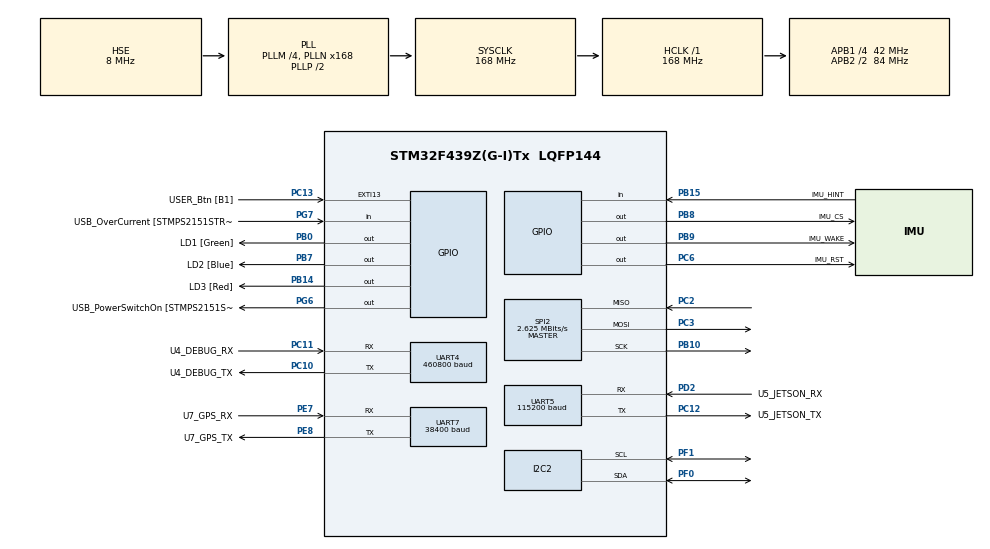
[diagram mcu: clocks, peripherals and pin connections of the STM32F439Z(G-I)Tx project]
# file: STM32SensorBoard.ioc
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Dma.Request0=UART4_TX
Dma.Request1=UART5_TX
Dma.Request2=UART7_RX
Dma.Request3=UART5_RX
Dma.Request4=UART4_RX
Dma.Request5=UART7_TX
Dma.UART4_RX.4.Direction=DMA_PERIPH_TO_MEMORY
Dma.UART4_RX.4.FIFOMode=DMA_FIFOMODE_DISABLE
Dma.UART4_RX.4.Instance=DMA1_Stream2
Dma.UART4_RX.4.MemDataAlignment=DMA_MDATAALIGN_BYTE
Dma.UART4_RX.4.MemInc=DMA_MINC_ENABLE
Dma.UART4_RX.4.Mode=DMA_NORMAL
Dma.UART4_RX.4.PeriphDataAlignment=DMA_PDATAALIGN_BYTE
Dma.UART4_RX.4.PeriphInc=DMA_PINC_DISABLE
Dma.UART4_RX.4.Priority=DMA_PRIORITY_LOW
Dma.UART4_TX.0.Direction=DMA_MEMORY_TO_PERIPH
Dma.UART4_TX.0.FIFOMode=DMA_FIFOMODE_DISABLE
Dma.UART4_TX.0.Instance=DMA1_Stream4
Dma.UART4_TX.0.MemDataAlignment=DMA_MDATAALIGN_BYTE
Dma.UART4_TX.0.MemInc=DMA_MINC_ENABLE
Dma.UART4_TX.0.Mode=DMA_NORMAL
Dma.UART4_TX.0.PeriphDataAlignment=DMA_PDATAALIGN_BYTE
Dma.UART4_TX.0.PeriphInc=DMA_PINC_DISABLE
Dma.UART4_TX.0.Priority=DMA_PRIORITY_LOW
Dma.UART5_RX.3.Direction=DMA_PERIPH_TO_MEMORY
Dma.UART5_RX.3.FIFOMode=DMA_FIFOMODE_DISABLE
Dma.UART5_RX.3.Instance=DMA1_Stream0
Dma.UART5_RX.3.MemDataAlignment=DMA_MDATAALIGN_BYTE
Dma.UART5_RX.3.MemInc=DMA_MINC_ENABLE
Dma.UART5_RX.3.Mode=DMA_NORMAL
Dma.UART5_RX.3.PeriphDataAlignment=DMA_PDATAALIGN_BYTE
Dma.UART5_RX.3.PeriphInc=DMA_PINC_DISABLE
Dma.UART5_RX.3.Priority=DMA_PRIORITY_LOW
Dma.UART5_TX.1.Direction=DMA_MEMORY_TO_PERIPH
Dma.UART5_TX.1.FIFOMode=DMA_FIFOMODE_DISABLE
Dma.UART5_TX.1.Instance=DMA1_Stream7
Dma.UART5_TX.1.MemDataAlignment=DMA_MDATAALIGN_BYTE
Dma.UART5_TX.1.MemInc=DMA_MINC_ENABLE
Dma.UART5_TX.1.Mode=DMA_NORMAL
Dma.UART5_TX.1.PeriphDataAlignment=DMA_PDATAALIGN_BYTE
Dma.UART5_TX.1.PeriphInc=DMA_PINC_DISABLE
Dma.UART5_TX.1.Priority=DMA_PRIORITY_HIGH
Dma.UART7_RX.2.Direction=DMA_PERIPH_TO_MEMORY
Dma.UART7_RX.2.FIFOMode=DMA_FIFOMODE_DISABLE
Dma.UART7_RX.2.Instance=DMA1_Stream3
Dma.UART7_RX.2.MemDataAlignment=DMA_MDATAALIGN_BYTE
Dma.UART7_RX.2.MemInc=DMA_MINC_ENABLE
Dma.UART7_RX.2.Mode=DMA_NORMAL
Dma.UART7_RX.2.PeriphDataAlignment=DMA_PDATAALIGN_BYTE
Dma.UART7_RX.2.PeriphInc=DMA_PINC_DISABLE
Dma.UART7_RX.2.Priority=DMA_PRIORITY_MEDIUM
Dma.UART7_TX.5.Direction=DMA_MEMORY_TO_PERIPH
Dma.UART7_TX.5.FIFOMode=DMA_FIFOMODE_DISABLE
Dma.UART7_TX.5.Instance=DMA1_Stream1
Dma.UART7_TX.5.MemDataAlignment=DMA_MDATAALIGN_BYTE
Dma.UART7_TX.5.MemInc=DMA_MINC_ENABLE
Dma.UART7_TX.5.Mode=DMA_NORMAL
Dma.UART7_TX.5.PeriphDataAlignment=DMA_PDATAALIGN_BYTE
Dma.UART7_TX.5.PeriphInc=DMA_PINC_DISABLE
Dma.UART7_TX.5.Priority=DMA_PRIORITY_LOW
FREERTOS.Tasks01=appMain,24,128,StartAppMainTask,As weak,NULL,Dynamic,NULL,NULL
FREERTOS.configUSE_NEWLIB_REENTRANT=1
Mcu.Family=STM32F4
Mcu.Name=STM32F439Z(G-I)Tx
Mcu.Package=LQFP144
NVIC.DMA1_Stream0_IRQn=true\:5\:0\:false\:false\:true\:true\:false\:true\:true
NVIC.DMA1_Stream1_IRQn=true\:5\:0\:false\:false\:true\:true\:false\:true\:true
NVIC.DMA1_Stream2_IRQn=true\:5\:0\:false\:false\:true\:true\:false\:true\:true
NVIC.DMA1_Stream3_IRQn=true\:5\:0\:false\:false\:true\:true\:false\:true\:true
NVIC.DMA1_Stream4_IRQn=true\:5\:0\:false\:false\:true\:true\:false\:true\:true
NVIC.DMA1_Stream7_IRQn=true\:5\:0\:false\:false\:true\:true\:false\:true\:true
NVIC.PriorityGroup=NVIC_PRIORITYGROUP_4
NVIC.TIM7_IRQn=true\:15\:0\:false\:false\:true\:false\:false\:true\:true
NVIC.TimeBase=TIM7_IRQn
NVIC.TimeBaseIP=TIM7
NVIC.UART4_IRQn=true\:5\:0\:false\:false\:true\:true\:true\:true\:true
NVIC.UART5_IRQn=true\:5\:0\:false\:false\:true\:true\:true\:true\:true
NVIC.UART7_IRQn=true\:5\:0\:false\:false\:true\:true\:true\:true\:true
PA1.GPIO_Label=RMII_REF_CLK [LAN8742A-CZ-TR_REFCLK0]
PA1.Signal=ETH_REF_CLK
PA10.GPIO_Label=USB_ID
PA10.Signal=USB_OTG_FS_ID
PA11.GPIO_Label=USB_DM
PA11.Signal=USB_OTG_FS_DM
PA12.GPIO_Label=USB_DP
PA12.Signal=USB_OTG_FS_DP
PA13.GPIO_Label=TMS
PA13.Mode=Serial_Wire
PA13.Signal=SYS_JTMS-SWDIO
PA14.GPIO_Label=TCK
PA14.Mode=Serial_Wire
PA14.Signal=SYS_JTCK-SWCLK
PA2.GPIO_Label=RMII_MDIO [LAN8742A-CZ-TR_MDIO]
PA2.Signal=ETH_MDIO
PA7.GPIO_Label=RMII_CRS_DV [LAN8742A-CZ-TR_CRS_DV]
PA7.Signal=ETH_CRS_DV
PA8.GPIO_Label=USB_SOF [TP1]
PA8.Signal=USB_OTG_FS_SOF
PA9.GPIO_Label=USB_VBUS
PA9.Signal=USB_OTG_FS_VBUS
PB0.GPIO_Label=LD1 [Green]
PB0.Signal=GPIO_Output
PB10.Mode=Full_Duplex_Master
PB10.Signal=SPI2_SCK
PB13.GPIO_Label=RMII_TXD1 [LAN8742A-CZ-TR_TXD1]
PB13.Signal=ETH_TXD1
PB14.GPIO_Label=LD3 [Red]
PB14.Signal=GPIO_Output
PB15.GPIO_Label=IMU_HINT
PB15.Signal=GPIO_Input
PB7.GPIO_Label=LD2 [Blue]
PB7.Signal=GPIO_Output
PB8.GPIO_Label=IMU_CS
PB8.Signal=GPIO_Output
PB9.GPIO_Label=IMU_WAKE
PB9.Signal=GPIO_Output
PC1.GPIO_Label=RMII_MDC [LAN8742A-CZ-TR_MDC]
PC1.Signal=ETH_MDC
PC10.GPIO_Label=U4_DEBUG_TX
PC10.Mode=Asynchronous
PC10.Signal=UART4_TX
PC11.GPIO_Label=U4_DEBUG_RX
PC11.Mode=Asynchronous
PC11.Signal=UART4_RX
PC12.GPIO_Label=U5_JETSON_TX
PC12.Mode=Asynchronous
PC12.Signal=UART5_TX
PC13.GPIO_Label=USER_Btn [B1]
PC13.Signal=GPXTI13
PC14/OSC32_IN.Mode=LSE-External-Oscillator
PC14/OSC32_IN.Signal=RCC_OSC32_IN
PC15/OSC32_OUT.Mode=LSE-External-Oscillator
PC15/OSC32_OUT.Signal=RCC_OSC32_OUT
PC2.Mode=Full_Duplex_Master
PC2.Signal=SPI2_MISO
PC3.Mode=Full_Duplex_Master
PC3.Signal=SPI2_MOSI
PC4.GPIO_Label=RMII_RXD0 [LAN8742A-CZ-TR_RXD0]
PC4.Signal=ETH_RXD0
PC5.GPIO_Label=RMII_RXD1 [LAN8742A-CZ-TR_RXD1]
PC5.Signal=ETH_RXD1
PC6.GPIO_Label=IMU_RST
PC6.Signal=GPIO_Output
PD2.GPIO_Label=U5_JETSON_RX
PD2.Mode=Asynchronous
PD2.Signal=UART5_RX
PD8.GPIO_Label=STLK_RX [STM32F103CBT6_PA3]
PD8.Signal=USART3_TX
PD9.GPIO_Label=STLK_TX [STM32F103CBT6_PA2]
PD9.Signal=USART3_RX
PE7.GPIO_Label=U7_GPS_RX
PE7.Mode=Asynchronous
PE7.Signal=UART7_RX
PE8.GPIO_Label=U7_GPS_TX
PE8.Mode=Asynchronous
PE8.Signal=UART7_TX
PF0.Mode=I2C
PF0.Signal=I2C2_SDA
PF1.Mode=I2C
PF1.Signal=I2C2_SCL
PG11.GPIO_Label=RMII_TX_EN [LAN8742A-CZ-TR_TXEN]
PG11.Signal=ETH_TX_EN
PG13.GPIO_Label=RMII_TXD0 [LAN8742A-CZ-TR_TXD0]
PG13.Signal=ETH_TXD0
PG6.GPIO_Label=USB_PowerSwitchOn [STMPS2151STR_EN]
PG6.Signal=GPIO_Output
PG7.GPIO_Label=USB_OverCurrent [STMPS2151STR_FAULT]
PG7.Signal=GPIO_Input
PH0/OSC_IN.GPIO_Label=MCO [STM32F103CBT6_PA8]
PH0/OSC_IN.Mode=HSE-External-Clock-Source
PH0/OSC_IN.Signal=RCC_OSC_IN
PH1/OSC_OUT.Mode=HSE-External-Clock-Source
PH1/OSC_OUT.Signal=RCC_OSC_OUT
ProjectManager.HeapSize=0x200
ProjectManager.StackSize=0x400
ProjectManager.TargetToolchain=CMake
RCC.48MHZClocksFreq_Value=48000000
RCC.AHBFreq_Value=168000000
RCC.APB1CLKDivider=RCC_HCLK_DIV4
RCC.APB1Freq_Value=42000000
RCC.APB1TimFreq_Value=84000000
RCC.APB2CLKDivider=RCC_HCLK_DIV2
RCC.APB2Freq_Value=84000000
RCC.APB2TimCLKDivider=2
RCC.APB2TimFreq_Value=168000000
RCC.CortexFreq_Value=168000000
RCC.HCLKFreq_Value=168000000
RCC.HSE_VALUE=8000000
RCC.HSI_VALUE=16000000
RCC.PLLM=4
RCC.PLLMUL=RCC_PLL_MUL9
RCC.PLLN=168
RCC.PLLQ=7
RCC.PLLSourceVirtual=RCC_PLLSOURCE_HSE
RCC.PRESCALERUSB=RCC_USBCLKSOURCE_PLL_DIV1_5
RCC.SYSCLKFreq_VALUE=168000000
RCC.SYSCLKSource=RCC_SYSCLKSOURCE_PLLCLK
RCC.SYSCLKSourceVirtual=RCC_SYSCLKSOURCE_PLLCLK
RCC.USBFreq_Value=48000000
RCC.VCOOutputFreq_Value=336000000
SPI2.BaudRatePrescaler=SPI_BAUDRATEPRESCALER_16
SPI2.CalculateBaudRate=2.625 MBits/s
SPI2.Direction=SPI_DIRECTION_2LINES
SPI2.Mode=SPI_MODE_MASTER
SPI2.VirtualType=VM_MASTER
UART4.BaudRate=460800
UART4.VirtualMode=Asynchronous
UART5.BaudRate=115200
UART5.VirtualMode=Asynchronous
UART7.BaudRate=38400
UART7.VirtualMode=Asynchronous
VP_FREERTOS_VS_CMSIS_V2.Mode=CMSIS_V2
VP_SYS_VS_tim7.Mode=TIM7
board=NUCLEO-F439ZI

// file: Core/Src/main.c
/* USER CODE BEGIN Header */
/**
  ******************************************************************************
  * @file           : main.c
  * @brief          : Main program body
  ******************************************************************************
  * @attention
  *
  * Copyright (c) 2026 STMicroelectronics.
  * All rights reserved.
  *
  * This software is licensed under terms that can be found in the LICENSE file
  * in the root directory of this software component.
  * If no LICENSE file comes with this software, it is provided AS-IS.
  *
  ******************************************************************************
  */
/* USER CODE END Header */
#include "main.h"
#include "cmsis_os.h"

/* USER CODE BEGIN Includes */
#include "appmain.h"
/* USER CODE END Includes */

I2C_HandleTypeDef hi2c2;

UART_HandleTypeDef huart4;
UART_HandleTypeDef huart5;
UART_HandleTypeDef huart7;
DMA_HandleTypeDef hdma_uart4_tx;
DMA_HandleTypeDef hdma_uart4_rx;
DMA_HandleTypeDef hdma_uart5_tx;
DMA_HandleTypeDef hdma_uart5_rx;
DMA_HandleTypeDef hdma_uart7_rx;
DMA_HandleTypeDef hdma_uart7_tx;

/* Definitions for appMain */
osThreadId_t appMainHandle;
const osThreadAttr_t appMain_attributes = {
  .name = "appMain",
  .stack_size = 128 * 4,
  .priority = (osPriority_t) osPriorityNormal,
};

void SystemClock_Config(void);
static void MX_GPIO_Init(void);
static void MX_DMA_Init(void);
static void MX_UART4_Init(void);
static void MX_UART5_Init(void);
static void MX_UART7_Init(void);
static void MX_SPI2_Init(void);
static void MX_I2C2_Init(void);
void StartAppMainTask(void *argument);

int main(void)
{

  /* MCU Configuration--------------------------------------------------------*/

  /* Reset of all peripherals, Initializes the Flash interface and the Systick. */
  HAL_Init();

  /* Configure the system clock */
  SystemClock_Config();

  /* Initialize all configured peripherals */
  MX_GPIO_Init();
  MX_DMA_Init();
  MX_UART4_Init();
  MX_UART5_Init();
  MX_UART7_Init();
  MX_SPI2_Init();
  MX_I2C2_Init();

  /* Init scheduler */
  osKernelInitialize();

  /* Create the thread(s) */
  /* creation of appMain */
  appMainHandle = osThreadNew(StartAppMainTask, NULL, &appMain_attributes);

  /* USER CODE BEGIN RTOS_THREADS */
  AppSetup();
  /* USER CODE END RTOS_THREADS */

  /* Start scheduler */
  osKernelStart();

  /* We should never get here as control is now taken by the scheduler */

  /* Infinite loop */
  while (1)
  {

  }
}

void SystemClock_Config(void)
{
  RCC_OscInitTypeDef RCC_OscInitStruct = {0};
  RCC_ClkInitTypeDef RCC_ClkInitStruct = {0};

  /** Configure the main internal regulator output voltage
  */
  __HAL_RCC_PWR_CLK_ENABLE();
  __HAL_PWR_VOLTAGESCALING_CONFIG(PWR_REGULATOR_VOLTAGE_SCALE1);

  /** Initializes the RCC Oscillators according to the specified parameters
  * in the RCC_OscInitTypeDef structure.
  */
  RCC_OscInitStruct.OscillatorType = RCC_OSCILLATORTYPE_HSE;
  RCC_OscInitStruct.HSEState = RCC_HSE_BYPASS;
  RCC_OscInitStruct.PLL.PLLState = RCC_PLL_ON;
  RCC_OscInitStruct.PLL.PLLSource = RCC_PLLSOURCE_HSE;
  RCC_OscInitStruct.PLL.PLLM = 4;
  RCC_OscInitStruct.PLL.PLLN = 168;
  RCC_OscInitStruct.PLL.PLLP = RCC_PLLP_DIV2;
  RCC_OscInitStruct.PLL.PLLQ = 7;
  if (HAL_RCC_OscConfig(&RCC_OscInitStruct) != HAL_OK)
  {
    Error_Handler();
  }

  /** Initializes the CPU, AHB and APB buses clocks
  */
  RCC_ClkInitStruct.ClockType = RCC_CLOCKTYPE_HCLK|RCC_CLOCKTYPE_SYSCLK
                              |RCC_CLOCKTYPE_PCLK1|RCC_CLOCKTYPE_PCLK2;
  RCC_ClkInitStruct.SYSCLKSource = RCC_SYSCLKSOURCE_PLLCLK;
  RCC_ClkInitStruct.AHBCLKDivider = RCC_SYSCLK_DIV1;
  RCC_ClkInitStruct.APB1CLKDivider = RCC_HCLK_DIV4;
  RCC_ClkInitStruct.APB2CLKDivider = RCC_HCLK_DIV2;

  if (HAL_RCC_ClockConfig(&RCC_ClkInitStruct, FLASH_LATENCY_5) != HAL_OK)
  {
    Error_Handler();
  }
}

static void MX_I2C2_Init(void)
{

  hi2c2.Instance = I2C2;
  hi2c2.Init.ClockSpeed = 100000;
  hi2c2.Init.DutyCycle = I2C_DUTYCYCLE_2;
  hi2c2.Init.OwnAddress1 = 0;
  hi2c2.Init.AddressingMode = I2C_ADDRESSINGMODE_7BIT;
  hi2c2.Init.DualAddressMode = I2C_DUALADDRESS_DISABLE;
  hi2c2.Init.OwnAddress2 = 0;
  hi2c2.Init.GeneralCallMode = I2C_GENERALCALL_DISABLE;
  hi2c2.Init.NoStretchMode = I2C_NOSTRETCH_DISABLE;
  if (HAL_I2C_Init(&hi2c2) != HAL_OK)
  {
    Error_Handler();
  }

  /** Configure Analogue filter
  */
  if (HAL_I2CEx_ConfigAnalogFilter(&hi2c2, I2C_ANALOGFILTER_ENABLE) != HAL_OK)
  {
    Error_Handler();
  }

  /** Configure Digital filter
  */
  if (HAL_I2CEx_ConfigDigitalFilter(&hi2c2, 0) != HAL_OK)
  {
    Error_Handler();
  }

}

static void MX_SPI2_Init(void)
{

  LL_SPI_InitTypeDef SPI_InitStruct = {0};

  LL_GPIO_InitTypeDef GPIO_InitStruct = {0};

  /* Peripheral clock enable */
  LL_APB1_GRP1_EnableClock(LL_APB1_GRP1_PERIPH_SPI2);

  LL_AHB1_GRP1_EnableClock(LL_AHB1_GRP1_PERIPH_GPIOC);
  LL_AHB1_GRP1_EnableClock(LL_AHB1_GRP1_PERIPH_GPIOB);
  /**SPI2 GPIO Configuration
  PC2   ------> SPI2_MISO
  PC3   ------> SPI2_MOSI
  PB10   ------> SPI2_SCK
  */
  GPIO_InitStruct.Pin = LL_GPIO_PIN_2|LL_GPIO_PIN_3;
  GPIO_InitStruct.Mode = LL_GPIO_MODE_ALTERNATE;
  GPIO_InitStruct.Speed = LL_GPIO_SPEED_FREQ_VERY_HIGH;
  GPIO_InitStruct.OutputType = LL_GPIO_OUTPUT_PUSHPULL;
  GPIO_InitStruct.Pull = LL_GPIO_PULL_NO;
  GPIO_InitStruct.Alternate = LL_GPIO_AF_5;
  LL_GPIO_Init(GPIOC, &GPIO_InitStruct);

  GPIO_InitStruct.Pin = LL_GPIO_PIN_10;
  GPIO_InitStruct.Mode = LL_GPIO_MODE_ALTERNATE;
  GPIO_InitStruct.Speed = LL_GPIO_SPEED_FREQ_VERY_HIGH;
  GPIO_InitStruct.OutputType = LL_GPIO_OUTPUT_PUSHPULL;
  GPIO_InitStruct.Pull = LL_GPIO_PULL_NO;
  GPIO_InitStruct.Alternate = LL_GPIO_AF_5;
  LL_GPIO_Init(GPIOB, &GPIO_InitStruct);

  /* SPI2 parameter configuration*/
  SPI_InitStruct.TransferDirection = LL_SPI_FULL_DUPLEX;
  SPI_InitStruct.Mode = LL_SPI_MODE_MASTER;
  SPI_InitStruct.DataWidth = LL_SPI_DATAWIDTH_8BIT;
  SPI_InitStruct.ClockPolarity = LL_SPI_POLARITY_LOW;
  SPI_InitStruct.ClockPhase = LL_SPI_PHASE_1EDGE;
  SPI_InitStruct.NSS = LL_SPI_NSS_SOFT;
  SPI_InitStruct.BaudRate = LL_SPI_BAUDRATEPRESCALER_DIV16;
  SPI_InitStruct.BitOrder = LL_SPI_MSB_FIRST;
  SPI_InitStruct.CRCCalculation = LL_SPI_CRCCALCULATION_DISABLE;
  SPI_InitStruct.CRCPoly = 10;
  LL_SPI_Init(SPI2, &SPI_InitStruct);
  LL_SPI_SetStandard(SPI2, LL_SPI_PROTOCOL_MOTOROLA);

}

static void MX_UART4_Init(void)
{

  huart4.Instance = UART4;
  huart4.Init.BaudRate = 460800;
  huart4.Init.WordLength = UART_WORDLENGTH_8B;
  huart4.Init.StopBits = UART_STOPBITS_1;
  huart4.Init.Parity = UART_PARITY_NONE;
  huart4.Init.Mode = UART_MODE_TX_RX;
  huart4.Init.HwFlowCtl = UART_HWCONTROL_NONE;
  huart4.Init.OverSampling = UART_OVERSAMPLING_16;
  if (HAL_UART_Init(&huart4) != HAL_OK)
  {
    Error_Handler();
  }

}

static void MX_UART5_Init(void)
{

  huart5.Instance = UART5;
  huart5.Init.BaudRate = 115200;
  huart5.Init.WordLength = UART_WORDLENGTH_8B;
  huart5.Init.StopBits = UART_STOPBITS_1;
  huart5.Init.Parity = UART_PARITY_NONE;
  huart5.Init.Mode = UART_MODE_TX_RX;
  huart5.Init.HwFlowCtl = UART_HWCONTROL_NONE;
  huart5.Init.OverSampling = UART_OVERSAMPLING_16;
  if (HAL_UART_Init(&huart5) != HAL_OK)
  {
    Error_Handler();
  }

}

static void MX_UART7_Init(void)
{

  huart7.Instance = UART7;
  huart7.Init.BaudRate = 38400;
  huart7.Init.WordLength = UART_WORDLENGTH_8B;
  huart7.Init.StopBits = UART_STOPBITS_1;
  huart7.Init.Parity = UART_PARITY_NONE;
  huart7.Init.Mode = UART_MODE_TX_RX;
  huart7.Init.HwFlowCtl = UART_HWCONTROL_NONE;
  huart7.Init.OverSampling = UART_OVERSAMPLING_16;
  if (HAL_UART_Init(&huart7) != HAL_OK)
  {
    Error_Handler();
  }

}

static void MX_DMA_Init(void)
{

  /* DMA controller clock enable */
  __HAL_RCC_DMA1_CLK_ENABLE();

  /* DMA interrupt init */
  /* DMA1_Stream0_IRQn interrupt configuration */
  HAL_NVIC_SetPriority(DMA1_Stream0_IRQn, 5, 0);
  HAL_NVIC_EnableIRQ(DMA1_Stream0_IRQn);
  /* DMA1_Stream1_IRQn interrupt configuration */
  HAL_NVIC_SetPriority(DMA1_Stream1_IRQn, 5, 0);
  HAL_NVIC_EnableIRQ(DMA1_Stream1_IRQn);
  /* DMA1_Stream2_IRQn interrupt configuration */
  HAL_NVIC_SetPriority(DMA1_Stream2_IRQn, 5, 0);
  HAL_NVIC_EnableIRQ(DMA1_Stream2_IRQn);
  /* DMA1_Stream3_IRQn interrupt configuration */
  HAL_NVIC_SetPriority(DMA1_Stream3_IRQn, 5, 0);
  HAL_NVIC_EnableIRQ(DMA1_Stream3_IRQn);
  /* DMA1_Stream4_IRQn interrupt configuration */
  HAL_NVIC_SetPriority(DMA1_Stream4_IRQn, 5, 0);
  HAL_NVIC_EnableIRQ(DMA1_Stream4_IRQn);
  /* DMA1_Stream7_IRQn interrupt configuration */
  HAL_NVIC_SetPriority(DMA1_Stream7_IRQn, 5, 0);
  HAL_NVIC_EnableIRQ(DMA1_Stream7_IRQn);

}

static void MX_GPIO_Init(void)
{
  GPIO_InitTypeDef GPIO_InitStruct = {0};

  /* GPIO Ports Clock Enable */
  __HAL_RCC_GPIOC_CLK_ENABLE();
  __HAL_RCC_GPIOF_CLK_ENABLE();
  __HAL_RCC_GPIOH_CLK_ENABLE();
  __HAL_RCC_GPIOA_CLK_ENABLE();
  __HAL_RCC_GPIOB_CLK_ENABLE();
  __HAL_RCC_GPIOE_CLK_ENABLE();
  __HAL_RCC_GPIOD_CLK_ENABLE();
  __HAL_RCC_GPIOG_CLK_ENABLE();

  /*Configure GPIO pin Output Level */
  HAL_GPIO_WritePin(GPIOB, LD1_Pin|LD3_Pin|LD2_Pin|IMU_CS_Pin
                          |IMU_WAKE_Pin, GPIO_PIN_RESET);

  /*Configure GPIO pin Output Level */
  HAL_GPIO_WritePin(USB_PowerSwitchOn_GPIO_Port, USB_PowerSwitchOn_Pin, GPIO_PIN_RESET);

  /*Configure GPIO pin Output Level */
  HAL_GPIO_WritePin(IMU_RST_GPIO_Port, IMU_RST_Pin, GPIO_PIN_RESET);

  /*Configure GPIO pin : USER_Btn_Pin */
  GPIO_InitStruct.Pin = USER_Btn_Pin;
  GPIO_InitStruct.Mode = GPIO_MODE_IT_RISING;
  GPIO_InitStruct.Pull = GPIO_NOPULL;
  HAL_GPIO_Init(USER_Btn_GPIO_Port, &GPIO_InitStruct);

  /*Configure GPIO pins : RMII_MDC_Pin RMII_RXD0_Pin RMII_RXD1_Pin */
  GPIO_InitStruct.Pin = RMII_MDC_Pin|RMII_RXD0_Pin|RMII_RXD1_Pin;
  GPIO_InitStruct.Mode = GPIO_MODE_AF_PP;
  GPIO_InitStruct.Pull = GPIO_NOPULL;
  GPIO_InitStruct.Speed = GPIO_SPEED_FREQ_VERY_HIGH;
  GPIO_InitStruct.Alternate = GPIO_AF11_ETH;
  HAL_GPIO_Init(GPIOC, &GPIO_InitStruct);

  /*Configure GPIO pins : RMII_REF_CLK_Pin RMII_MDIO_Pin RMII_CRS_DV_Pin */
  GPIO_InitStruct.Pin = RMII_REF_CLK_Pin|RMII_MDIO_Pin|RMII_CRS_DV_Pin;
  GPIO_InitStruct.Mode = GPIO_MODE_AF_PP;
  GPIO_InitStruct.Pull = GPIO_NOPULL;
  GPIO_InitStruct.Speed = GPIO_SPEED_FREQ_VERY_HIGH;
  GPIO_InitStruct.Alternate = GPIO_AF11_ETH;
  HAL_GPIO_Init(GPIOA, &GPIO_InitStruct);

  /*Configure GPIO pins : LD1_Pin LD3_Pin LD2_Pin IMU_CS_Pin
                           IMU_WAKE_Pin */
  GPIO_InitStruct.Pin = LD1_Pin|LD3_Pin|LD2_Pin|IMU_CS_Pin
                          |IMU_WAKE_Pin;
  GPIO_InitStruct.Mode = GPIO_MODE_OUTPUT_PP;
  GPIO_InitStruct.Pull = GPIO_NOPULL;
  GPIO_InitStruct.Speed = GPIO_SPEED_FREQ_LOW;
  HAL_GPIO_Init(GPIOB, &GPIO_InitStruct);

  /*Configure GPIO pin : RMII_TXD1_Pin */
  GPIO_InitStruct.Pin = RMII_TXD1_Pin;
  GPIO_InitStruct.Mode = GPIO_MODE_AF_PP;
  GPIO_InitStruct.Pull = GPIO_NOPULL;
  GPIO_InitStruct.Speed = GPIO_SPEED_FREQ_VERY_HIGH;
  GPIO_InitStruct.Alternate = GPIO_AF11_ETH;
  HAL_GPIO_Init(RMII_TXD1_GPIO_Port, &GPIO_InitStruct);

  /*Configure GPIO pin : IMU_HINT_Pin */
  GPIO_InitStruct.Pin = IMU_HINT_Pin;
  GPIO_InitStruct.Mode = GPIO_MODE_INPUT;
  GPIO_InitStruct.Pull = GPIO_NOPULL;
  HAL_GPIO_Init(IMU_HINT_GPIO_Port, &GPIO_InitStruct);

  /*Configure GPIO pins : STLK_RX_Pin STLK_TX_Pin */
  GPIO_InitStruct.Pin = STLK_RX_Pin|STLK_TX_Pin;
  GPIO_InitStruct.Mode = GPIO_MODE_AF_PP;
  GPIO_InitStruct.Pull = GPIO_NOPULL;
  GPIO_InitStruct.Speed = GPIO_SPEED_FREQ_VERY_HIGH;
  GPIO_InitStruct.Alternate = GPIO_AF7_USART3;
  HAL_GPIO_Init(GPIOD, &GPIO_InitStruct);

  /*Configure GPIO pin : USB_PowerSwitchOn_Pin */
  GPIO_InitStruct.Pin = USB_PowerSwitchOn_Pin;
  GPIO_InitStruct.Mode = GPIO_MODE_OUTPUT_PP;
  GPIO_InitStruct.Pull = GPIO_NOPULL;
  GPIO_InitStruct.Speed = GPIO_SPEED_FREQ_LOW;
  HAL_GPIO_Init(USB_PowerSwitchOn_GPIO_Port, &GPIO_InitStruct);

  /*Configure GPIO pin : USB_OverCurrent_Pin */
  GPIO_InitStruct.Pin = USB_OverCurrent_Pin;
  GPIO_InitStruct.Mode = GPIO_MODE_INPUT;
  GPIO_InitStruct.Pull = GPIO_NOPULL;
  HAL_GPIO_Init(USB_OverCurrent_GPIO_Port, &GPIO_InitStruct);

  /*Configure GPIO pin : IMU_RST_Pin */
  GPIO_InitStruct.Pin = IMU_RST_Pin;
  GPIO_InitStruct.Mode = GPIO_MODE_OUTPUT_PP;
  GPIO_InitStruct.Pull = GPIO_NOPULL;
  GPIO_InitStruct.Speed = GPIO_SPEED_FREQ_LOW;
  HAL_GPIO_Init(IMU_RST_GPIO_Port, &GPIO_InitStruct);

  /*Configure GPIO pins : USB_SOF_Pin USB_ID_Pin USB_DM_Pin USB_DP_Pin */
  GPIO_InitStruct.Pin = USB_SOF_Pin|USB_ID_Pin|USB_DM_Pin|USB_DP_Pin;
  GPIO_InitStruct.Mode = GPIO_MODE_AF_PP;
  GPIO_InitStruct.Pull = GPIO_NOPULL;
  GPIO_InitStruct.Speed = GPIO_SPEED_FREQ_VERY_HIGH;
  GPIO_InitStruct.Alternate = GPIO_AF10_OTG_FS;
  HAL_GPIO_Init(GPIOA, &GPIO_InitStruct);

  /*Configure GPIO pin : USB_VBUS_Pin */
  GPIO_InitStruct.Pin = USB_VBUS_Pin;
  GPIO_InitStruct.Mode = GPIO_MODE_INPUT;
  GPIO_InitStruct.Pull = GPIO_NOPULL;
  HAL_GPIO_Init(USB_VBUS_GPIO_Port, &GPIO_InitStruct);

  /*Configure GPIO pins : RMII_TX_EN_Pin RMII_TXD0_Pin */
  GPIO_InitStruct.Pin = RMII_TX_EN_Pin|RMII_TXD0_Pin;
  GPIO_InitStruct.Mode = GPIO_MODE_AF_PP;
  GPIO_InitStruct.Pull = GPIO_NOPULL;
  GPIO_InitStruct.Speed = GPIO_SPEED_FREQ_VERY_HIGH;
  GPIO_InitStruct.Alternate = GPIO_AF11_ETH;
  HAL_GPIO_Init(GPIOG, &GPIO_InitStruct);

}

__weak void StartAppMainTask(void *argument)
{
  for(;;)
  {
    osDelay(1);
  }
}

void HAL_TIM_PeriodElapsedCallback(TIM_HandleTypeDef *htim)
{
  if (htim->Instance == TIM7)
  {
    HAL_IncTick();
  }
}

void Error_Handler(void)
{
  __disable_irq();
  while (1)
  {
  }
}
